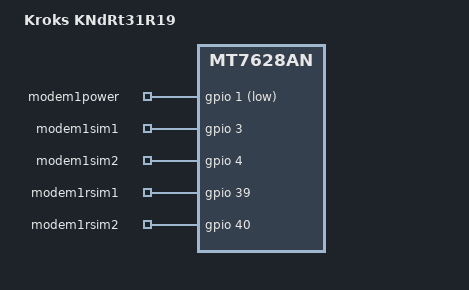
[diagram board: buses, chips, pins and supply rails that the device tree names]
// SPDX-License-Identifier: GPL-2.0-or-later OR MIT

#include "mt7628an_kroks.dtsi"

/ {
	compatible = "kroks,kndrt31r19", "mediatek,mt7628an-soc";
	model = "Kroks KNdRt31R19";

	leds {
		status {
			label = "red:status";
		};

		wifi {
			label = "yellow:wifi";
		};
	};

	gpio_export {
		compatible = "gpio-export";
		#size-cells = <0>;

		modem1power {
			gpio-export,name = "modem1power";
			gpio-export,output = <0>;
			gpios = <&gpio 1 GPIO_ACTIVE_LOW>;
		};

		modem1sim1 {
			gpio-export,name = "modem1sim1";
			gpio-export,output = <1>;
			gpios = <&gpio 3 GPIO_ACTIVE_HIGH>;
		};

		modem1sim2 {
			gpio-export,name = "modem1sim2";
			gpio-export,output = <0>;
			gpios = <&gpio 4 GPIO_ACTIVE_HIGH>;
		};

		modem1rsim1 {
			gpio-export,name = "modem1rsim1";
			gpio-export,output = <0>;
			gpios = <&gpio 39 GPIO_ACTIVE_HIGH>;
		};

		modem1rsim2 {
			gpio-export,name = "modem1rsim2";
			gpio-export,output = <0>;
			gpios = <&gpio 40 GPIO_ACTIVE_HIGH>;
		};
	};
};

&esw {
	mediatek,portmap = <0x2f>;
};

&state_default {
	gpio {
		groups = "i2s", "i2c", "p4led_an", "p3led_an", "wled_an";
		function = "gpio";
	};
};
